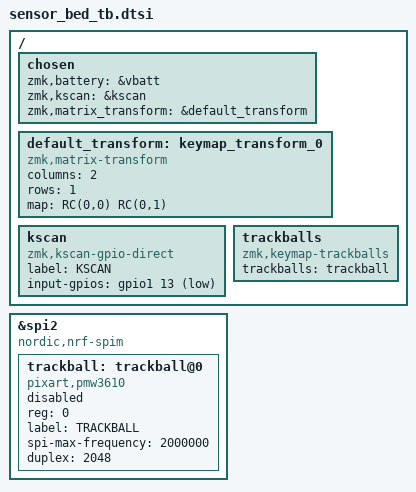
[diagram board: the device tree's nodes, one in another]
/*
 * Copyright (c) 2020 The ZMK Contributors
 *
 * SPDX-License-Identifier: MIT
 */

#include <dt-bindings/zmk/matrix_transform.h>

/* blade-specific: common settings */ 
/ {

	chosen: chosen {
		zmk,battery = &vbatt;
		zmk,kscan = &kscan;
		zmk,matrix_transform = &default_transform;
	};

/* global matrix transform */
	default_transform: keymap_transform_0 {
		compatible = "zmk,matrix-transform";
		columns = <2>;
		rows = <1>;
		map = <
          RC(0,0) RC(0,1)
		>;

	};

  /* Scan matrix declaration */
	kscan: kscan {
		compatible = "zmk,kscan-gpio-direct";
		label = "KSCAN";
		input-gpios
	  = <&gpio1 13 (GPIO_ACTIVE_LOW | GPIO_PULL_UP)>;
	};

  /* Configure trackballs (either split can have the trackball) */
	trackballs {
		compatible = "zmk,keymap-trackballs";
		trackballs = <&trackball>;
	};

};

/* Declare the trackball */
&spi2 {
  compatible = "nordic,nrf-spim";

  trackball: trackball@0 {
    compatible = "pixart,pmw3610";
    status = "disabled";
    reg = <0>;
    label = "TRACKBALL";
    spi-max-frequency = <2000000>;
    duplex = <2048>; // required by 3-wire spi
  };
};
